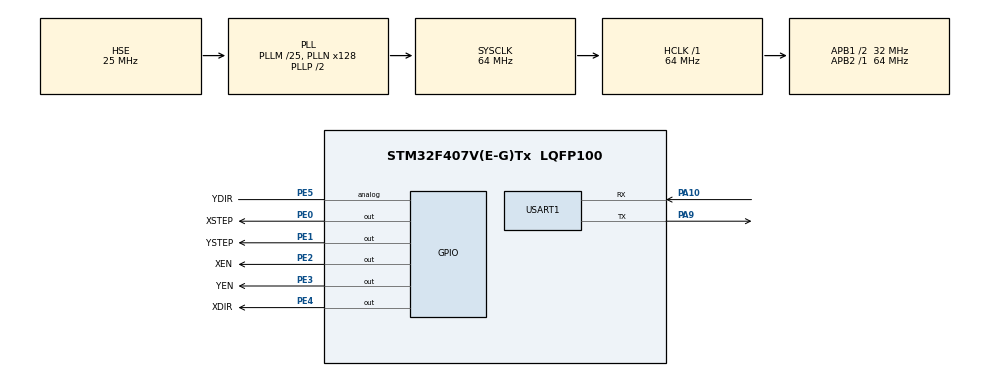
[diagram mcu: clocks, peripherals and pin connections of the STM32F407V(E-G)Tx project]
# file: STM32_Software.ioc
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FREERTOS.Tasks01=defaultTask,24,128,StartDefaultTask,Default,NULL,Dynamic,NULL,NULL;CoreXY_Control,24,256,StartTask02,Default,NULL,Dynamic,NULL,NULL
Mcu.Family=STM32F4
Mcu.Name=STM32F407V(E-G)Tx
Mcu.Package=LQFP100
NVIC.PriorityGroup=NVIC_PRIORITYGROUP_4
NVIC.TIM1_UP_TIM10_IRQn=true\:15\:0\:false\:false\:true\:false\:false\:true\:true
NVIC.TimeBase=TIM1_UP_TIM10_IRQn
NVIC.TimeBaseIP=TIM10
PA10.Mode=Asynchronous
PA10.Signal=USART1_RX
PA13.Mode=Serial_Wire
PA13.Signal=SYS_JTMS-SWDIO
PA14.Mode=Serial_Wire
PA14.Signal=SYS_JTCK-SWCLK
PA9.Mode=Asynchronous
PA9.Signal=USART1_TX
PC14-OSC32_IN.Mode=LSE-External-Oscillator
PC14-OSC32_IN.Signal=RCC_OSC32_IN
PC15-OSC32_OUT.Mode=LSE-External-Oscillator
PC15-OSC32_OUT.Signal=RCC_OSC32_OUT
PE0.GPIO_Label=XSTEP
PE0.Signal=GPIO_Output
PE1.GPIO_Label=YSTEP
PE1.Signal=GPIO_Output
PE2.GPIO_Label=XEN
PE2.Signal=GPIO_Output
PE3.GPIO_Label=YEN
PE3.Signal=GPIO_Output
PE4.GPIO_Label=XDIR
PE4.Signal=GPIO_Output
PE5.GPIO_Label=YDIR
PE5.Signal=GPIO_Analog
PH0-OSC_IN.Mode=HSE-External-Oscillator
PH0-OSC_IN.Signal=RCC_OSC_IN
PH1-OSC_OUT.Mode=HSE-External-Oscillator
PH1-OSC_OUT.Signal=RCC_OSC_OUT
ProjectManager.HeapSize=0x400
ProjectManager.StackSize=0x400
ProjectManager.TargetToolchain=MDK-ARM V5.32
RCC.48MHZClocksFreq_Value=32000000
RCC.AHBFreq_Value=64000000
RCC.APB1CLKDivider=RCC_HCLK_DIV2
RCC.APB1Freq_Value=32000000
RCC.APB1TimFreq_Value=64000000
RCC.APB2Freq_Value=64000000
RCC.APB2TimFreq_Value=64000000
RCC.CortexFreq_Value=64000000
RCC.HCLKFreq_Value=64000000
RCC.HSE_VALUE=25000000
RCC.HSI_VALUE=16000000
RCC.PLLM=25
RCC.PLLN=128
RCC.PLLSourceVirtual=RCC_PLLSOURCE_HSE
RCC.SYSCLKFreq_VALUE=64000000
RCC.SYSCLKSource=RCC_SYSCLKSOURCE_PLLCLK
RCC.VCOOutputFreq_Value=128000000
USART1.VirtualMode=VM_ASYNC
VP_FREERTOS_VS_CMSIS_V2.Mode=CMSIS_V2
VP_SYS_VS_tim10.Mode=TIM10
board=custom

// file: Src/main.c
/* USER CODE BEGIN Header */
/**
  ******************************************************************************
  * @file           : main.c
  * @brief          : Main program body
  ******************************************************************************
  * @attention
  *
  * Copyright (c) 2023 STMicroelectronics.
  * All rights reserved.
  *
  * This software is licensed under terms that can be found in the LICENSE file
  * in the root directory of this software component.
  * If no LICENSE file comes with this software, it is provided AS-IS.
  *
  ******************************************************************************
  */
/* USER CODE END Header */
#include "main.h"
#include "cmsis_os.h"
#include "usart.h"
#include "gpio.h"

void SystemClock_Config(void);
void MX_FREERTOS_Init(void);

int main(void)
{

  /* MCU Configuration--------------------------------------------------------*/

  /* Reset of all peripherals, Initializes the Flash interface and the Systick. */
  HAL_Init();

  /* Configure the system clock */
  SystemClock_Config();

  /* Initialize all configured peripherals */
  MX_GPIO_Init();
  MX_USART1_UART_Init();

  /* Init scheduler */
  osKernelInitialize();  /* Call init function for freertos objects (in freertos.c) */
  MX_FREERTOS_Init();

  /* Start scheduler */
  osKernelStart();
  /* We should never get here as control is now taken by the scheduler */
  /* Infinite loop */
  while (1)
  {

  }
}

void SystemClock_Config(void)
{
  RCC_OscInitTypeDef RCC_OscInitStruct = {0};
  RCC_ClkInitTypeDef RCC_ClkInitStruct = {0};

  /** Configure the main internal regulator output voltage
  */
  __HAL_RCC_PWR_CLK_ENABLE();
  __HAL_PWR_VOLTAGESCALING_CONFIG(PWR_REGULATOR_VOLTAGE_SCALE1);

  /** Initializes the RCC Oscillators according to the specified parameters
  * in the RCC_OscInitTypeDef structure.
  */
  RCC_OscInitStruct.OscillatorType = RCC_OSCILLATORTYPE_HSE;
  RCC_OscInitStruct.HSEState = RCC_HSE_ON;
  RCC_OscInitStruct.PLL.PLLState = RCC_PLL_ON;
  RCC_OscInitStruct.PLL.PLLSource = RCC_PLLSOURCE_HSE;
  RCC_OscInitStruct.PLL.PLLM = 25;
  RCC_OscInitStruct.PLL.PLLN = 128;
  RCC_OscInitStruct.PLL.PLLP = RCC_PLLP_DIV2;
  RCC_OscInitStruct.PLL.PLLQ = 4;
  if (HAL_RCC_OscConfig(&RCC_OscInitStruct) != HAL_OK)
  {
    Error_Handler();
  }

  /** Initializes the CPU, AHB and APB buses clocks
  */
  RCC_ClkInitStruct.ClockType = RCC_CLOCKTYPE_HCLK|RCC_CLOCKTYPE_SYSCLK
                              |RCC_CLOCKTYPE_PCLK1|RCC_CLOCKTYPE_PCLK2;
  RCC_ClkInitStruct.SYSCLKSource = RCC_SYSCLKSOURCE_PLLCLK;
  RCC_ClkInitStruct.AHBCLKDivider = RCC_SYSCLK_DIV1;
  RCC_ClkInitStruct.APB1CLKDivider = RCC_HCLK_DIV2;
  RCC_ClkInitStruct.APB2CLKDivider = RCC_HCLK_DIV1;

  if (HAL_RCC_ClockConfig(&RCC_ClkInitStruct, FLASH_LATENCY_2) != HAL_OK)
  {
    Error_Handler();
  }
}

void HAL_TIM_PeriodElapsedCallback(TIM_HandleTypeDef *htim)
{
  if (htim->Instance == TIM10) {
    HAL_IncTick();
  }
}

void Error_Handler(void)
{
  __disable_irq();
  while (1)
  {
  }
}

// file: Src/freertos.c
/* USER CODE BEGIN Header */
/**
  ******************************************************************************
  * File Name          : freertos.c
  * Description        : Code for freertos applications
  ******************************************************************************
  * @attention
  *
  * Copyright (c) 2023 STMicroelectronics.
  * All rights reserved.
  *
  * This software is licensed under terms that can be found in the LICENSE file
  * in the root directory of this software component.
  * If no LICENSE file comes with this software, it is provided AS-IS.
  *
  ******************************************************************************
  */
/* USER CODE END Header */

#include "FreeRTOS.h"
#include "task.h"
#include "main.h"
#include "cmsis_os.h"

/* Definitions for defaultTask */
osThreadId_t defaultTaskHandle;
const osThreadAttr_t defaultTask_attributes = {
  .name = "defaultTask",
  .stack_size = 128 * 4,
  .priority = (osPriority_t) osPriorityNormal,
};
/* Definitions for CoreXY_Control */
osThreadId_t CoreXY_ControlHandle;
const osThreadAttr_t CoreXY_Control_attributes = {
  .name = "CoreXY_Control",
  .stack_size = 256 * 4,
  .priority = (osPriority_t) osPriorityNormal,
};

void StartDefaultTask(void *argument);
void StartTask02(void *argument);

void MX_FREERTOS_Init(void); /* (MISRA C 2004 rule 8.1) */

void MX_FREERTOS_Init(void) {

  /* Create the thread(s) */
  /* creation of defaultTask */
  defaultTaskHandle = osThreadNew(StartDefaultTask, NULL, &defaultTask_attributes);

  /* creation of CoreXY_Control */
  CoreXY_ControlHandle = osThreadNew(StartTask02, NULL, &CoreXY_Control_attributes);

}

void StartDefaultTask(void *argument)
{
  for(;;)
  {
    osDelay(1);
  }
}

void StartTask02(void *argument)
{
  for(;;)
  {
    osDelay(1);
  }
}

/* USER CODE BEGIN Application */
void defaultTask(void)
{

}

void CoreXY_Control(int x, int y)
{

}
/* USER CODE END Application */
